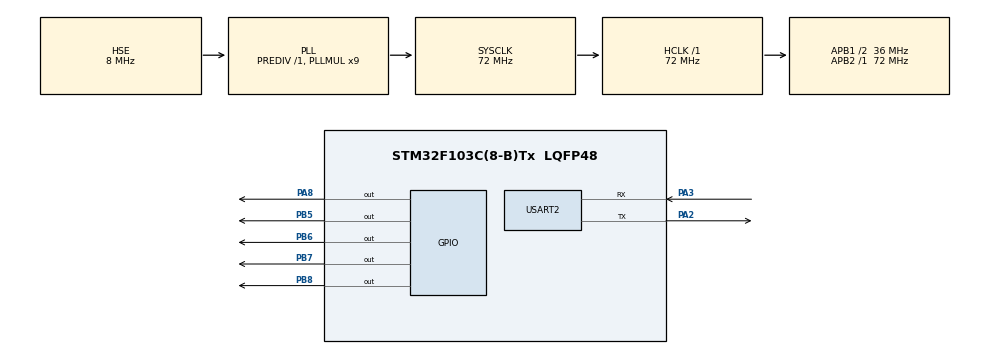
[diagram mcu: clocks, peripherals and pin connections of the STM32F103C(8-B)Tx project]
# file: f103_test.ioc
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FREERTOS.Tasks01=defaultTask,24,128,StartDefaultTask,Default,NULL,Dynamic,NULL,NULL
FREERTOS.configCHECK_FOR_STACK_OVERFLOW=2
FREERTOS.configTOTAL_HEAP_SIZE=8192
FREERTOS.configUSE_MALLOC_FAILED_HOOK=1
Mcu.Family=STM32F1
Mcu.Name=STM32F103C(8-B)Tx
Mcu.Package=LQFP48
NVIC.PriorityGroup=NVIC_PRIORITYGROUP_4
NVIC.TIM3_IRQn=true\:5\:0\:false\:false\:true\:true\:true\:true\:true
NVIC.TIM4_IRQn=true\:15\:0\:false\:false\:true\:false\:false\:true\:true
NVIC.TimeBase=TIM4_IRQn
NVIC.TimeBaseIP=TIM4
NVIC.USART2_IRQn=true\:5\:0\:false\:false\:true\:true\:true\:true\:true
PA13.Mode=Serial_Wire
PA13.Signal=SYS_JTMS-SWDIO
PA14.Mode=Serial_Wire
PA14.Signal=SYS_JTCK-SWCLK
PA2.Mode=Asynchronous
PA2.Signal=USART2_TX
PA3.Mode=Asynchronous
PA3.Signal=USART2_RX
PA8.Signal=GPIO_Output
PB5.Signal=GPIO_Output
PB6.Signal=GPIO_Output
PB7.Signal=GPIO_Output
PB8.Signal=GPIO_Output
PC14-OSC32_IN.Mode=LSE-External-Oscillator
PC14-OSC32_IN.Signal=RCC_OSC32_IN
PC15-OSC32_OUT.Mode=LSE-External-Oscillator
PC15-OSC32_OUT.Signal=RCC_OSC32_OUT
PD0-OSC_IN.Mode=HSE-External-Oscillator
PD0-OSC_IN.Signal=RCC_OSC_IN
PD1-OSC_OUT.Mode=HSE-External-Oscillator
PD1-OSC_OUT.Signal=RCC_OSC_OUT
ProjectManager.HeapSize=0x200
ProjectManager.StackSize=0x400
ProjectManager.TargetToolchain=MDK-ARM V5.32
RCC.AHBFreq_Value=72000000
RCC.APB1CLKDivider=RCC_HCLK_DIV2
RCC.APB1Freq_Value=36000000
RCC.APB1TimFreq_Value=72000000
RCC.APB2Freq_Value=72000000
RCC.APB2TimFreq_Value=72000000
RCC.HCLKFreq_Value=72000000
RCC.PLLMUL=RCC_PLL_MUL9
RCC.PLLSourceVirtual=RCC_PLLSOURCE_HSE
RCC.RTCClockSelection=RCC_RTCCLKSOURCE_LSE
RCC.SYSCLKFreq_VALUE=72000000
RCC.SYSCLKSource=RCC_SYSCLKSOURCE_PLLCLK
RCC.USBFreq_Value=72000000
TIM3.AutoReloadPreload=TIM_AUTORELOAD_PRELOAD_ENABLE
TIM3.Period=999
TIM3.Prescaler=71
USART2.VirtualMode=VM_ASYNC
VP_FREERTOS_VS_CMSIS_V2.Mode=CMSIS_V2
VP_RTC_VS_RTC_Activate.Mode=RTC_Enabled
VP_SYS_VS_tim4.Mode=TIM4
VP_TIM3_VS_ClockSourceINT.Mode=Internal
board=custom

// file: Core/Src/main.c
/* USER CODE BEGIN Header */
/**
  ******************************************************************************
  * @file           : main.c
  * @brief          : Main program body
  ******************************************************************************
  * @attention
  *
  * Copyright (c) 2026 STMicroelectronics.
  * All rights reserved.
  *
  * This software is licensed under terms that can be found in the LICENSE file
  * in the root directory of this software component.
  * If no LICENSE file comes with this software, it is provided AS-IS.
  *
  ******************************************************************************
  */
/* USER CODE END Header */
#include "main.h"
#include "cmsis_os.h"
#include "rtc.h"
#include "tim.h"
#include "usart.h"
#include "gpio.h"

/* USER CODE BEGIN Includes */
#include "oled.h"
#include "delay.h"
#include "stepper.h"
#include "mpu6050.h"
/* USER CODE END Includes */

void SystemClock_Config(void);
void MX_FREERTOS_Init(void);
/* USER CODE BEGIN PFP */
void HAL_TIM_PeriodElapsedCallback(TIM_HandleTypeDef *htim);
/* USER CODE END PFP */

int main(void)
{

  /* MCU Configuration--------------------------------------------------------*/

  /* Reset of all peripherals, Initializes the Flash interface and the Systick. */
  HAL_Init();

  /* Configure the system clock */
  SystemClock_Config();

  /* Initialize all configured peripherals */
  MX_GPIO_Init();
  MX_RTC_Init();
  MX_TIM3_Init();
  MX_USART2_UART_Init();
  /* USER CODE BEGIN 2 */
  // OLED_Init();
  // Stepper_Init();

  // uint8_t mpu_init_result = MPU6050_Init();
  // if(mpu_init_result) OLED_ShowString(1, 1, "init failed!");
  // else OLED_ShowString(1, 1, "init success!");

//  MPU6050_Calibrate_GyroAcc(&att);
//  att.last_time = HAL_GetTick(); // get the current time in milliseconds
  /* USER CODE END 2 */

  /* Init scheduler */
  osKernelInitialize();  /* Call init function for freertos objects (in cmsis_os2.c) */
  MX_FREERTOS_Init();

  /* Start scheduler */
  osKernelStart();

  /* We should never get here as control is now taken by the scheduler */

  /* Infinite loop */
  while (1)
  {

    /* USER CODE BEGIN 3 */
    // Stepper_PID_UpdateSpeed(&rollmoto_pid, &rollmoto_state, att.roll); // 横滚角控制电机姿态闭环
    // Stepper_SetSpeed(rollmoto_pid.output, &rollmoto_state);

  }
  /* USER CODE END 3 */
}

void SystemClock_Config(void)
{
  RCC_OscInitTypeDef RCC_OscInitStruct = {0};
  RCC_ClkInitTypeDef RCC_ClkInitStruct = {0};
  RCC_PeriphCLKInitTypeDef PeriphClkInit = {0};

  /** Initializes the RCC Oscillators according to the specified parameters
  * in the RCC_OscInitTypeDef structure.
  */
  RCC_OscInitStruct.OscillatorType = RCC_OSCILLATORTYPE_HSE|RCC_OSCILLATORTYPE_LSE;
  RCC_OscInitStruct.HSEState = RCC_HSE_ON;
  RCC_OscInitStruct.HSEPredivValue = RCC_HSE_PREDIV_DIV1;
  RCC_OscInitStruct.LSEState = RCC_LSE_ON;
  RCC_OscInitStruct.HSIState = RCC_HSI_ON;
  RCC_OscInitStruct.PLL.PLLState = RCC_PLL_ON;
  RCC_OscInitStruct.PLL.PLLSource = RCC_PLLSOURCE_HSE;
  RCC_OscInitStruct.PLL.PLLMUL = RCC_PLL_MUL9;
  if (HAL_RCC_OscConfig(&RCC_OscInitStruct) != HAL_OK)
  {
    Error_Handler();
  }

  /** Initializes the CPU, AHB and APB buses clocks
  */
  RCC_ClkInitStruct.ClockType = RCC_CLOCKTYPE_HCLK|RCC_CLOCKTYPE_SYSCLK
                              |RCC_CLOCKTYPE_PCLK1|RCC_CLOCKTYPE_PCLK2;
  RCC_ClkInitStruct.SYSCLKSource = RCC_SYSCLKSOURCE_PLLCLK;
  RCC_ClkInitStruct.AHBCLKDivider = RCC_SYSCLK_DIV1;
  RCC_ClkInitStruct.APB1CLKDivider = RCC_HCLK_DIV2;
  RCC_ClkInitStruct.APB2CLKDivider = RCC_HCLK_DIV1;

  if (HAL_RCC_ClockConfig(&RCC_ClkInitStruct, FLASH_LATENCY_2) != HAL_OK)
  {
    Error_Handler();
  }
  PeriphClkInit.PeriphClockSelection = RCC_PERIPHCLK_RTC;
  PeriphClkInit.RTCClockSelection = RCC_RTCCLKSOURCE_LSE;
  if (HAL_RCCEx_PeriphCLKConfig(&PeriphClkInit) != HAL_OK)
  {
    Error_Handler();
  }
}

void HAL_TIM_PeriodElapsedCallback(TIM_HandleTypeDef *htim)
{
  if (htim->Instance == TIM4)
  {
    HAL_IncTick();
  }
  /* USER CODE BEGIN Callback 1 */
  Stepper_TIM_ElapsedCallback(htim);    /* 无脑转发 */
  /* USER CODE END Callback 1 */
}

void Error_Handler(void)
{
  __disable_irq();
  while (1)
  {
  }
}

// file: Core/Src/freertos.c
/* USER CODE BEGIN Header */
/**
  ******************************************************************************
  * File Name          : freertos.c
  * Description        : Code for freertos applications
  ******************************************************************************
  * @attention
  *
  * Copyright (c) 2026 STMicroelectronics.
  * All rights reserved.
  *
  * This software is licensed under terms that can be found in the LICENSE file
  * in the root directory of this software component.
  * If no LICENSE file comes with this software, it is provided AS-IS.
  *
  ******************************************************************************
  */
/* USER CODE END Header */

#include "FreeRTOS.h"
#include "task.h"
#include "main.h"
#include "cmsis_os.h"

/* USER CODE BEGIN Includes */
#include "user_taskInit.h"
/* USER CODE END Includes */

/* Definitions for defaultTask */
osThreadId_t defaultTaskHandle;
const osThreadAttr_t defaultTask_attributes = {
  .name = "defaultTask",
  .stack_size = 128 * 4,
  .priority = (osPriority_t) osPriorityLow,
};

void StartDefaultTask(void *argument);

void MX_FREERTOS_Init(void); /* (MISRA C 2004 rule 8.1) */

/* Hook prototypes */
void vApplicationStackOverflowHook(xTaskHandle xTask, signed char *pcTaskName);
void vApplicationMallocFailedHook(void);

/* USER CODE BEGIN 4 */
void vApplicationStackOverflowHook(xTaskHandle xTask, signed char *pcTaskName)
{
   /* Run time stack overflow checking is performed if
   configCHECK_FOR_STACK_OVERFLOW is defined to 1 or 2. This hook function is
   called if a stack overflow is detected. */
   (void)xTask;
   (void)pcTaskName;
  taskDISABLE_INTERRUPTS();
  for(;;);          /* 或直接 __BKPT(0)，调试器会停在这儿 */
}
/* USER CODE END 4 */

/* USER CODE BEGIN 5 */
void vApplicationMallocFailedHook(void)
{
   /* vApplicationMallocFailedHook() will only be called if
   configUSE_MALLOC_FAILED_HOOK is set to 1 in FreeRTOSConfig.h. It is a hook
   function that will get called if a call to pvPortMalloc() fails.
   pvPortMalloc() is called internally by the kernel whenever a task, queue,
   timer or semaphore is created. It is also called by various parts of the
   demo application. If heap_1.c or heap_2.c are used, then the size of the
   heap available to pvPortMalloc() is defined by configTOTAL_HEAP_SIZE in
   FreeRTOSConfig.h, and the xPortGetFreeHeapSize() API function can be used
   to query the size of free heap space that remains (although it does not
   provide information on how the remaining heap might be fragmented). */
}
/* USER CODE END 5 */

void MX_FREERTOS_Init(void) {
  /* USER CODE BEGIN Init */
  userTaskInit();
  /* USER CODE END Init */

  /* Create the thread(s) */
  /* creation of defaultTask */
  defaultTaskHandle = osThreadNew(StartDefaultTask, NULL, &defaultTask_attributes);

}

void StartDefaultTask(void *argument)
{
  for(;;)
  {
    osDelay(1);
  }
}
